# bao1x register map
Vendor: baochip
Registers are 32-bit, read-write, reset 0x0 unless marked. A register's access mark holds for its fields unless they carry their own. Offsets are from the block's base; [hi:lo] are bit positions; 'fields as' and 'values as' point back to an identical list.

## PL230 — PL230 DMA Controller Core
Base 0x40011000
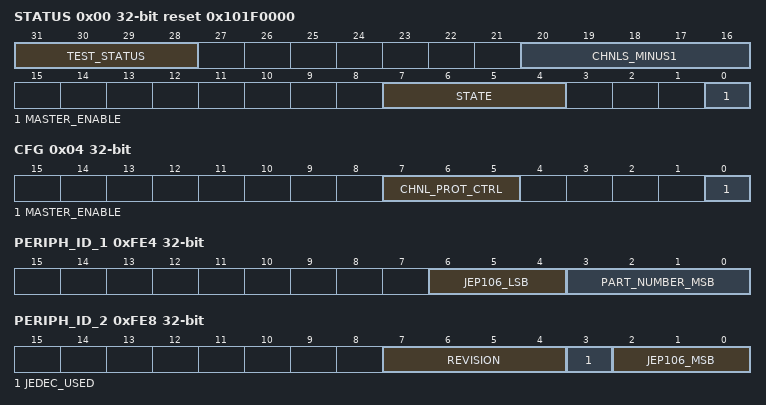
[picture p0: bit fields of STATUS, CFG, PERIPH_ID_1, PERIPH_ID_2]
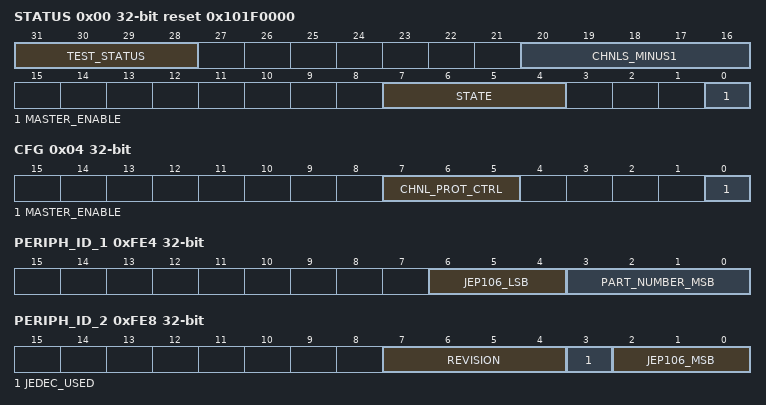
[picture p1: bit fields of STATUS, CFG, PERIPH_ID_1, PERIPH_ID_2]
0x00 STATUS ro reset 0x101F0000 (reset mask 0xFFFFFF0F) — DMA Status Register
  [31:28] TEST_STATUS — Test status configuration
  [20:16] CHNLS_MINUS1 — Number of available DMA channels minus 1
  [7:4] STATE — Current state of the control machine
  [0] MASTER_ENABLE — Master enable status
0x04 CFG reset not defined — DMA Configuration Register
  [7:5] CHNL_PROT_CTRL ro — Set AHB-Lite configuration
  [0] MASTER_ENABLE wo
0x08 CTRLBASEPTR — DMA Control Data Base Pointer Register
  [31:8] CTRL_BASE_PTR
0x0C ALTCTRLBASEPTR ro — DMA Channel Alternate Control Data Base Pointer Register
  [31:0] ALT_CTRL_BASE_PTR
0x10 DMA_WAITONREQ_STATUS ro — Channel wait on request status
  [7:0] DMA_WAITONREQ_STATUS — Wait on request status, one bit per channel
0x14 CHNLSWREQUEST wo reset not defined — DMA Channel Software Request Register
  [7:0] CHNL_SW_REQUEST
0x18 CHNLUSEBURSTSET — DMA Channel Useburst Set Register
  [7:0] CHNL_USEBURST_SET
0x1C CHNLUSEBURSTCLR wo reset not defined — DMA Channel Useburst Clear Register
  [7:0] CHNL_USEBURST_CLR
0x20 CHNLREQMASKSET — DMA Channel Request Mask Set Register
  [7:0] CHNL_REQ_MASK_SET
0x24 CHNLREQMASKCLR wo reset not defined — DMA Channel Request Mask Clear Register
  [7:0] CHNL_REQ_MASK_CLR
0x28 CHNLENABLESET — DMA Channel Enable Set Register
  [7:0] CHNL_ENABLE_SET
0x2C CHNLENABLECLR wo reset not defined — DMA Channel Enable Clear Register
  [7:0] CHNL_ENABLE_CLR
0x30 CHNLPRIALTSET — DMA Channel Primary-Alternate Set Register
  [7:0] CHNL_PRI_ALT_SET
0x34 CHNLPRIALTCLR wo reset not defined — DMA Channel Primary-Alternate Clear Register
  [7:0] CHNL_PRI_ALT_CLR
0x38 CHNLPRIORITYSET — DMA Channel Priority Set Register
  [7:0] CHNL_PRIORITY_SET
0x3C CHNLPRIORITYCLR wo reset not defined — DMA Channel Priority Clear Register
  [7:0] CHNL_PRIORITY_CLR
0x4C ERRCLR — DMA Bus Error Clear Register
  [0] ERR_CLR
0xFE0 PERIPH_ID_0 — Peripheral ID byte 0
  [7:0] PART_NUMBER_LSB ro — Identifies the part number
0xFE4 PERIPH_ID_1 — Peripheral ID byte 1
  [6:4] JEP106_LSB ro — Designer ID LSB
  [3:0] PART_NUMBER_MSB ro — Identifies the part number
0xFE8 PERIPH_ID_2 — Peripheral ID byte 2
  [7:4] REVISION ro — Identifies revision number of peripheral
  [3] JEDEC_USED ro — Identifies if JP106 ID code is used
  [2:0] JEP106_MSB ro — Designer ID MSB

## PL230 — PL230 DMA Controller Core
Base 0x40011000
0x00 STATUS ro reset 0x101F0000 (reset mask 0xFFFFFF0F) — DMA Status Register
  fields as STATUS
0x04 CFG wo reset not defined — DMA Configuration Register
  [7:5] CHNL_PROT_CTRL ro — Set AHB-Lite configuration
  [0] MASTER_ENABLE
0x08 CTRLBASEPTR — DMA Control Data Base Pointer Register
  [31:8] CTRL_BASE_PTR
0x0C ALTCTRLBASEPTR ro — DMA Channel Alternate Control Data Base Pointer Register
  [31:0] ALT_CTRL_BASE_PTR
0x10 DMA_WAITONREQ_STATUS ro — Channel wait on request status
  fields as DMA_WAITONREQ_STATUS
0x14 CHNLSWREQUEST wo reset not defined — DMA Channel Software Request Register
  [7:0] CHNL_SW_REQUEST
0x18 CHNLUSEBURSTSET — DMA Channel Useburst Set Register
  [7:0] CHNL_USEBURST_SET
0x1C CHNLUSEBURSTCLR wo reset not defined — DMA Channel Useburst Clear Register
  [7:0] CHNL_USEBURST_CLR
0x20 CHNLREQMASKSET — DMA Channel Request Mask Set Register
  [7:0] CHNL_REQ_MASK_SET
0x24 CHNLREQMASKCLR wo reset not defined — DMA Channel Request Mask Clear Register
  [7:0] CHNL_REQ_MASK_CLR
0x28 CHNLENABLESET — DMA Channel Enable Set Register
  [7:0] CHNL_ENABLE_SET
0x2C CHNLENABLECLR wo reset not defined — DMA Channel Enable Clear Register
  [7:0] CHNL_ENABLE_CLR
0x30 CHNLPRIALTSET — DMA Channel Primary-Alternate Set Register
  [7:0] CHNL_PRI_ALT_SET
0x34 CHNLPRIALTCLR wo reset not defined — DMA Channel Primary-Alternate Clear Register
  [7:0] CHNL_PRI_ALT_CLR
0x38 CHNLPRIORITYSET — DMA Channel Priority Set Register
  [7:0] CHNL_PRIORITY_SET
0x3C CHNLPRIORITYCLR wo reset not defined — DMA Channel Priority Clear Register
  [7:0] CHNL_PRIORITY_CLR
0x4C ERRCLR — DMA Bus Error Clear Register
  [0] ERR_CLR
0xFE0 PERIPH_ID_0 — Peripheral ID byte 0
  [7:0] PART_NUMBER_LSB ro — Identifies the part number
0xFE4 PERIPH_ID_1 — Peripheral ID byte 1
  fields as PERIPH_ID_1
0xFE8 PERIPH_ID_2 — Peripheral ID byte 2
  fields as PERIPH_ID_2
